# tviic2d6mddr register map
Vendor: Cypress Semiconductor; Series: tviic2d6mddr; File version: 1.0
CPU: CM7 r0p1, little endian, MPU, FPU, VTOR, 3 interrupt priority bits
Registers are 32-bit, read-write, reset 0x0 unless marked. A register's access mark holds for its fields unless they carry their own. Offsets are from the block's base; [hi:lo] are bit positions; lines under a group give offsets from that group; {n}, {i} and the like mark numbered series; 'fields as' and 'values as' point back to an identical list.

## VIDEOSS0 (part 10 of 18) — Video and Graphics Subsystem IP
Base 0x40A00000
0x80000 VIDEOIO group — Video I/O Core
  0x00 SUBIO group — Sub Interface
    0x10000 COMPENG group — Composition Engine
      {0x7400+0x400*l} LAYERBLEND{l} group (l=1..5) — LayerBlend #{l} (Display, Alpha Plane {l})
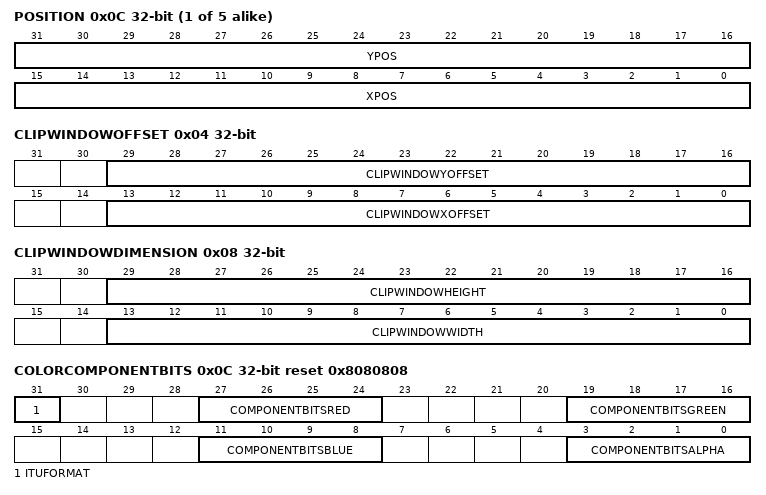
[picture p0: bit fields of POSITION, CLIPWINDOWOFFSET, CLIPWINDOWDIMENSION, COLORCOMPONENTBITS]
        0x0C POSITION — Position of secondary (overlay) input frame
          [31:16] YPOS — vertical position, first pixel is at 0, format s15 (twos complement) (format is signed integer)
          [15:0] XPOS — horizontal position, first pixel is at 0, format s15 (twos complement) (format is signed integer)
      0x8C00 EXTSRC8 group — ExtSrc #8 (Display)
        0x00 STATICCONTROL — ExtSrc static control register
          [8] STARTSEL — Start select selects the mode to start processing operations.
            0=INPUT (Free running mode, use the incoming command word as trigger to start processing.); 1=LOCAL (Keep to local start configuration, use external kick or SW trigger to start processing. The behavior is similar to fetch units.)
          [0] SHDEN — Enables shadowing of all RWS type registers (0=write_through, 1=shadowed).
        0x04 CLIPWINDOWOFFSET — Clip window offset, to generate a clipping of the frame. It has to be within the input frame.
          [29:16] CLIPWINDOWYOFFSET — Clip window offset in Y direction, relative to the frame origin.
          [13:0] CLIPWINDOWXOFFSET — Clip window offset in X direction, relative to the frame origin.
        0x08 CLIPWINDOWDIMENSION — Define the clip window dimension. If the clip window feature is enabled this dimension is used for the new frame dimension. Note that the clip window has to be smaller or equal to the original frame dimensions. The new frame has to be within the active area of the original frame.
          [29:16] CLIPWINDOWHEIGHT — Clip window height in pixels minus one.
          [13:0] CLIPWINDOWWIDTH — Clip window width in pixels minus one.
        0x0C COLORCOMPONENTBITS reset 0x8080808 — Color component size of raw input data. Please note that the width must be equal or lower than the output width.
          [31] ITUFORMAT — When ComponentBitsRed/Green/Blue is set to 10 and this mode enabled (value 1), then input format is considered 8.2 instead of 10.0 bits (max color is 1020 instead of 1023). This is compliant to ITU 656 standard.
          [27:24] COMPONENTBITSRED — Component size of red channel [0-10].
          [19:16] COMPONENTBITSGREEN — Component size of green channel [0-10].
          [11:8] COMPONENTBITSBLUE — Component size of blue channel [0-10].
          [3:0] COMPONENTBITSALPHA — Component size of alpha channel [0-8].
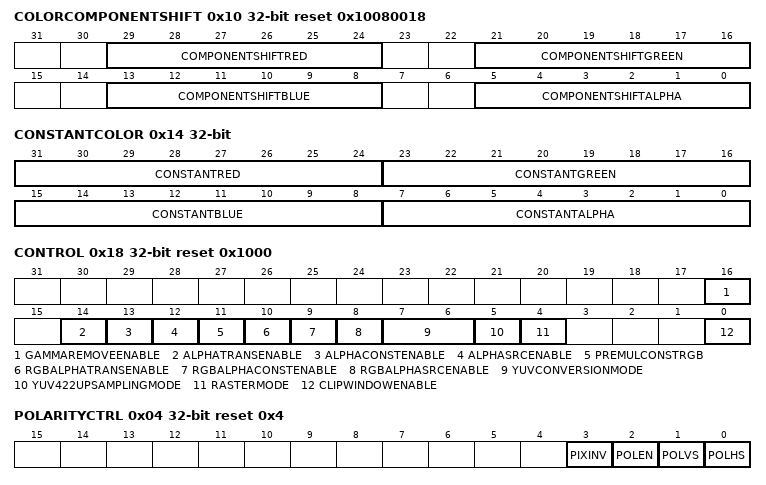
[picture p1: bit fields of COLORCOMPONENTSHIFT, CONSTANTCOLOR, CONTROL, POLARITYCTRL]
        0x10 COLORCOMPONENTSHIFT reset 0x10080018 — Color component offset of raw input data.
          [29:24] COMPONENTSHIFTRED — Offset for red component.
          [21:16] COMPONENTSHIFTGREEN — Offset for green component.
          [13:8] COMPONENTSHIFTBLUE — Offset for blue component.
          [5:0] COMPONENTSHIFTALPHA — Offset for alpha component.
        0x14 CONSTANTCOLOR
          [31:24] CONSTANTRED — Red or Y (luma).
          [23:16] CONSTANTGREEN — Green or U (chroma).
          [15:8] CONSTANTBLUE — Blue or V (chroma).
          [7:0] CONSTANTALPHA — Alpha.
        0x18 CONTROL reset 0x1000 — Common control settings.
          [16] GAMMAREMOVEENABLE — Value 1 enables the stage to remove a gamma from RGB components.
          [14] ALPHATRANSENABLE — Value 1 enables transparent alpha for computing the output alpha. When disabled transparent alpha is set to 1.
          [13] ALPHACONSTENABLE — Value 1 enables constant alpha for computing the output alpha. When disabled constant alpha is set to 1.
          [12] ALPHASRCENABLE — Value 1 enables source alpha for computing the output alpha. When disabled source alpha is set to 1.
          [11] PREMULCONSTRGB — When enabled (value 1) the values given by ConstantRed/Green/Blue are used instead of alpha for source RGB pre-multiply. Settings RGBAlphaSrc/Const/TransEnable have no effect then.
          [10] RGBALPHATRANSENABLE — Value 1 enables transparent alpha (0 or 1 depending on RGB matching ConstantColor setting) for RGB pre-multiply. When disabled transparent alpha is set to 1.
          [9] RGBALPHACONSTENABLE — Value 1 enables constant alpha (ConstAlpha field) for RGB pre-multiply. When disabled constant alpha is set to 1.
          [8] RGBALPHASRCENABLE — Value 1 enables source alpha (extracted from input stream) for RGB pre-multiply. When disabled source alpha is set to 1.
          [7:6] YUVCONVERSIONMODE — Enables different kind of YUV to RGB conversions.
            0=OFF (No conversion. Input data must be RGB.); 1=ITU601 (Conversion from YCbCr (YUV) to RGB according to ITU recommendation BT.601-6 (standard definition TV). Input range is 16..235 for Y and 16..240 for U/V.); 2=ITU601_FR (Conversion from YCbCr (YUV) to RGB according to ITU recommendation BT.601-6, but assuming full range YUV inputs (0..255). Most typically used for computer graphics (e.g. for JPEG encoding).); 3=ITU709 (Conversion from YCbCr (YUV) to RGB according to ITU recommendation BT.709-5 part 2 (high definition TV). Input range is 16..235 for Y and 16..240 for U/V.)
          [5] YUV422UPSAMPLINGMODE — Selects a method for horizontal up-sampling when RasterMode is YUV422.
            0=REPLICATE (Replicate mode for interspersed samples (UV samples between Y samples).); 1=INTERPOLATE (Interpolate mode for coaligned samples (UV samples at Y sample positions).)
          [4] RASTERMODE — Selects a method how generate output samples from input stream.
            0=NORMAL (Input stream is RGB(A) or YUV 4:4:4.); 1=YUV422 (Input stream is packed YUV 4:2:2.)
          [0] CLIPWINDOWENABLE — Value 1 enables the clip window feature.
        0x1C CONTROLTRIGGER wo reset not defined — ExtSrc unit trigger token generation
          [0] SHDTOKGEN — Write a 1 to this field for the extsrc unit to perform a shadow load with the next start of operation and set the rld bit in the start of frame control word (generate shadow load token for subsequent units).
        0x20 START wo reset not defined — ExtSrc unit start register
          [0] START — Writing a one starts processing, use this only for debug purposes.
  0x20000 DISENG0 group — Display Engine
    0x00 DISENGCFG0 group — Top-Level Configuration
      0x00 CTL reset 0x1 — Display engine control register.
        [0] DSPCLKDIVIDE — Controls generation of display clock signals for display stream.
          0=DIV1 (External display clock signal has pixel clock frequency.); 1=DIV2 (External display clock signal has twice the pixel clock frequency.)
      0x04 POLARITYCTRL reset 0x4 — Polarity control for TCon input and corresponding top-level output (TCon by-pass port).
        [3] PIXINV — Inversion of RGB data.
          0=NONINV (No inversion of pixel data); 1=INV (Pixel data inverted (1. complement))
        [2] POLEN — Polarity of Data_Enable signal.
          0=LOW (Low active); 1=HIGH (High active)
        [1] POLVS — Polarity of vsync signal.
          0=LOW (Low active); 1=HIGH (High active)
        [0] POLHS — Polarity of hsync signal.
          0=LOW (Low active); 1=HIGH (High active)
      0x10 SIGSELECT — Tap selection for Signature.
        [1:0] SIG_SELECT — Selects a source for Sig unit.
          0=NONE (No source.); 1=FRAMEGEN (Source is FrameGen output.); 2=GAMMACOR (Source is GammaCor output.); 3=DITHER (Source is Dither output.)
      0x14 HISTOGRAMSELECT — Tap selection for Histogram.
        [1:0] HISTOGRAM_SELECT — Selects a source for Histogram unit.
          values as VIDEOIO.DISENG0.DISENGCFG0.SIGSELECT.SIG_SELECT
      0x20 DUMPSELECT — Tap selection for Frame Dump.
        [9:8] DUMP_SELECT — Selects a source for FrameDump unit.
          values as VIDEOIO.DISENG0.DISENGCFG0.SIGSELECT.SIG_SELECT
    0x1000 SIG0 group — Signature Unit
      0x00 STATICCONTROL reset 0x8000000 — Global configuration shared by all evaluation windows.
        [31:24] ERRTHRESRESET — ErrThresReset must be programmed to value less than 255. Number of consecutive frames without signature violation before StsSigError is reset for an evaluation window. 0 means that each frame without violation will reset the status. The internal counter compared against this threshold is reset with each frame that has violation.
        [23:16] ERRTHRES — Number of frames with signature violation before StsSigError is set for an evaluation window. These frames do not need to be consecutive. 0 means that each frame with violation will set the status. The internal counter compared against this threshold is reset when 'ErrThreshReset' consecutive frames without signature violation occur.
        [4] SHDLDSEL — Source select for events that will load shadow registers into the active configuration.
          0=LOCAL (Shadows are loaded at start of frame for each evaluation window for which ShdLdReq has been set.); 1=GLOBAL (Shadows of all evaluation windows are loaded synchronous to the display stream (shadow load token received on frame input port).)
        [0] SHDEN — Enables shadow registers for RWS type fields (0 = write through, 1 = shadowed).
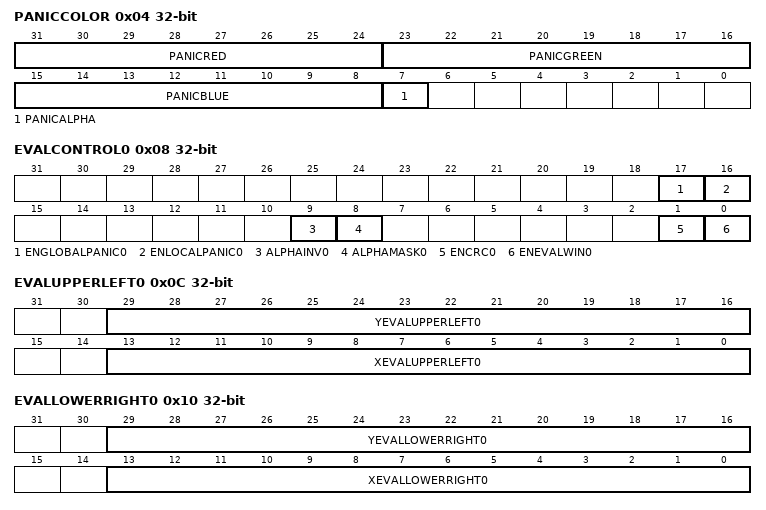
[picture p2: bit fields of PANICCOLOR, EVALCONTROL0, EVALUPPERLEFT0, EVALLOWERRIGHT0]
      0x04 PANICCOLOR — Overlay color for evaluation windows in panic mode.
        [31:24] PANICRED — Red color component.
        [23:16] PANICGREEN — Green color component.
        [15:8] PANICBLUE — Blue color component.
        [7] PANICALPHA — Alpha mask bit.
      0x08 EVALCONTROL0 — Control settings for evaluation window 0.
        [17] ENGLOBALPANIC0 — When enabled (value 1) the error status of this window (StsSigError) will activate the panic mode of the display stream's Frame Generator, which can switch to another display mode in response.
        [16] ENLOCALPANIC0 — When enabled (value 1) the error status this window (StsSigError) will replace all pixels inside the window by a constant color on the display. Skip regions due to other evaluation windows on top are not modified. AlphaMask, when enabled, is not considered for this replacement.
        [9] ALPHAINV0 — When enabled (value 1) the effect of AlphaMask is inverted (pixels with alpha bit = 1 are ignored then).
        [8] ALPHAMASK0 — When enabled (value 1) pixels with alpha bit = 0 are ignored for signature computation.
        [1] ENCRC0 — When enabled (value 1) the measured signature is checked against a reference value (SigCRCRef).
        [0] ENEVALWIN0 — When enabled (value 1) a CRC signature is computed for all pixels inside this evaluation window (SigCRC). When this bit is cleared, the internal status for this window is reset (StsSigError bit and frame counters).
      0x0C EVALUPPERLEFT0 — Upper left corner of evaluation window 0.
        [29:16] YEVALUPPERLEFT0 — Y coordinate.
        [13:0] XEVALUPPERLEFT0 — X coordinate.
      0x10 EVALLOWERRIGHT0 — Lower right corner of evaluation window 0.
        [29:16] YEVALLOWERRIGHT0 — Y coordinate.
        [13:0] XEVALLOWERRIGHT0 — X coordinate.
      0x14 SIGCRCREDREF0 reset 0xFFFFFFFF — Reference signature of red channel for evaluation window 0.
        [31:0] SIGCRCREDREF0 — Reference value that is compared against measured SigCRCRed value.
      0x18 SIGCRCGREENREF0 reset 0xFFFFFFFF — Reference signature of green channel for evaluation window 0.
        [31:0] SIGCRCGREENREF0 — Reference value that is compared against measured SigCRCGreen value.
      0x1C SIGCRCBLUEREF0 reset 0xFFFFFFFF — Reference signature of blue channel for evaluation window 0.
        [31:0] SIGCRCBLUEREF0 — Reference value that is compared against measured SigCRCBlue value.
      0x20 SIGCRCRED0 ro reset 0xFFFFFFFF — Measured signature of red channel for evaluation window 0.
        [31:0] SIGCRCRED0 — CRC values from red channel.
      0x24 SIGCRCGREEN0 ro reset 0xFFFFFFFF — Measured signature of green channel for evaluation window 0.
        [31:0] SIGCRCGREEN0 — CRC values from green channel.
      0x28 SIGCRCBLUE0 ro reset 0xFFFFFFFF — Measured signature of blue channel for evaluation window 0.
        [31:0] SIGCRCBLUE0 — CRC values from blue channel.
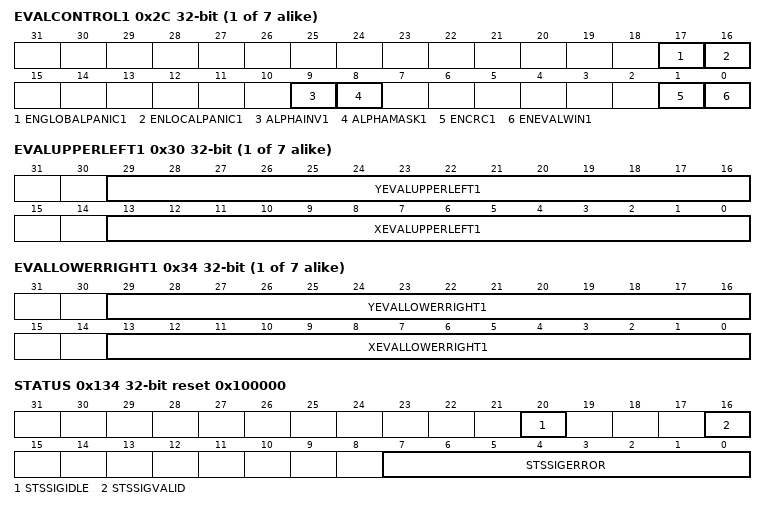
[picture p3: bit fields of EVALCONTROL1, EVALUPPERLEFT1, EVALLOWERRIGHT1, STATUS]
      {0x8+0x24*l} EVALCONTROL{l} (l=1..7) — Control settings for evaluation window {l}.
        [17] ENGLOBALPANIC{l} — See EnGlobalPanic0.
        [16] ENLOCALPANIC{l} — See EnLocalPanic0.
        [9] ALPHAINV{l} — See AlphaInv0.
        [8] ALPHAMASK{l} — See AlphaMask0.
        [1] ENCRC{l} — See EnCRC0.
        [0] ENEVALWIN{l} — See EnEvalWin0.
      {0xC+0x24*l} EVALUPPERLEFT{l} (l=1..7) — Upper left corner of evaluation window {l}.
        [29:16] YEVALUPPERLEFT{l} — See YEvalUpperLeft0.
        [13:0] XEVALUPPERLEFT{l} — See XEvalUpperLeft0.
      {0x10+0x24*l} EVALLOWERRIGHT{l} (l=1..7) — Lower right corner of evaluation window {l}.
        [29:16] YEVALLOWERRIGHT{l} — See YEvalLowerRight0.
        [13:0] XEVALLOWERRIGHT{l} — See XEvalLowerRight0.
      {0x14+0x24*l} SIGCRCREDREF{l} reset 0xFFFFFFFF (l=1..7) — Reference signature of red channel for evaluation window {l}.
        [31:0] SIGCRCREDREF{l} — See SigCRCRedRef0.
      {0x18+0x24*l} SIGCRCGREENREF{l} reset 0xFFFFFFFF (l=1..7) — Reference signature of green channel for evaluation window {l}.
        [31:0] SIGCRCGREENREF{l} — See SigCRCGreenRef0.
      {0x1C+0x24*l} SIGCRCBLUEREF{l} reset 0xFFFFFFFF (l=1..7) — Reference signature of blue channel for evaluation window {l}.
        [31:0] SIGCRCBLUEREF{l} — See SigCRCBlueRef0.
      {0x20+0x24*l} SIGCRCRED{l} ro reset 0xFFFFFFFF (l=1..7) — Measured signature of red channel for evaluation window {l}.
        [31:0] SIGCRCRED{l} — See SigCRCRed0.
      {0x24+0x24*l} SIGCRCGREEN{l} ro reset 0xFFFFFFFF (l=1..7) — Measured signature of green channel for evaluation window {l}.
        [31:0] SIGCRCGREEN{l} — See SigCRCGreen0.
      {0x28+0x24*l} SIGCRCBLUE{l} ro reset 0xFFFFFFFF (l=1..7) — Measured signature of blue channel for evaluation window {l}.
        [31:0] SIGCRCBLUE{l} — See SigCRCBlue0.
      0x128 SHADOWLOAD — Shadow load control register.
        [7:0] SHDLDREQ — Shadow load request for each evaluation window (bit index = window index). Writing a '1' to a bit will load the shadows into the active configuration for that window at start of next frame. Writing a '0' has no effect. The flag is reset by HW once the shadows have been loaded. A shadow load interrupt signal is generated when shadows have been loaded for at least one evaluation window. Has only effect when ShdLdSel is set to LOCAL.
      0x12C CONTINUOUSMODE — Signature operation mode control.
        [0] ENCONT — EnCont = 0: disables continuous mode. Signatures will be generated only once and in idle state after completion of measurement. In this 'ONE_TIME' mode the signature must be triggered by 'Kick' field. EnCont = 1: enables continuous mode. Write '1' to this field, signature starts and measures every incoming frame until EnCont is turned to 0. 'Kick' has no effect when 'EnCont' = 1.
      0x130 SOFTWAREKICK wo reset not defined — Signature measurement trigger.
        [0] KICK — ContinueMode.EnCont=0: Write '1' to this field in order to start signature computation with next frame. ContinueMode.EnCont=1: This field is ignored.
      0x134 STATUS ro reset 0x100000 — Module status.
        [20] STSSIGIDLE — StsSigIdle = 1: Signature is in Idle state. StsSigIdle = 0: Signature runs.
        [16] STSSIGVALID — Measured signature values are valid. This flag is set when the SigCRC fields have been updated for all enabled evaluation windows. In that case also the corresponding interrupt event is triggered. It is reset when SW writes a '1' to the 'Kick' field in order to start a new measurement.
        [7:0] STSSIGERROR — Error status bits for all evaluation windows (bit index = window index). When a bit is set it means that measured signature value is different from reference value (SigCRCRef). The bit is set when EnCRC is active and a certain number of frames have a violation (ErrThres). It is reset when the reference check for evaluation window is disabled (EnEvalWin or EnCRC) or in case a certain number of consecutive frames have no violation (ErrThresReset). The value corresponds to the panic status of this evaluation window.
    0x1400 HISTOGRAM0 group — Histogram Unit
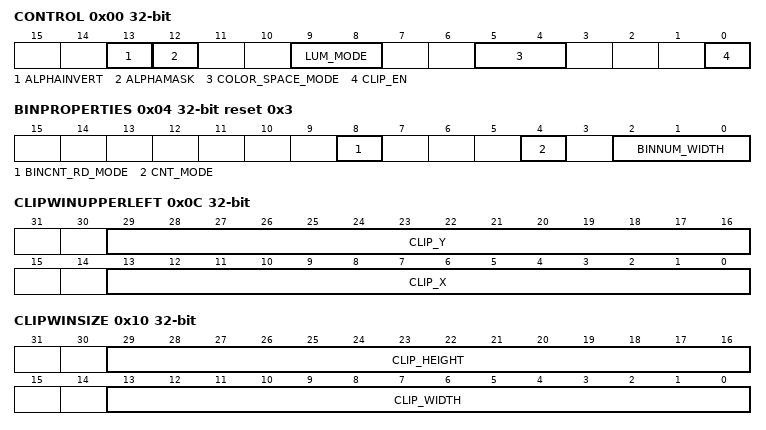
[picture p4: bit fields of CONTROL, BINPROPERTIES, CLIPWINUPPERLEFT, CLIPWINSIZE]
      0x00 CONTROL — Controls some settings concerning input components and alpha mask.
        [13] ALPHAINVERT — Value 1 inverts the effect of the alpha mask mode when enabled (pixels with alpha value smaller or equal 0.5 are affecting the histogram bins).
        [12] ALPHAMASK — Value 1 enables the alpha mask mode. In this mode only pixels with an alpha value larger than 0.5 are affecting the histogram bins.
        [9:8] LUM_MODE — If a histogram for luma or luminance is required, the conversion formula for luma (Y component according to BT.601) or luminance (Y component according to BT.709) can be selected here. Luma or luminance calculation should only be applied if RGB components in range [0..255] are delivered directly at histogram input or when YCrCb components are converted to RGB by the appropriate setting of register field color_space_mode. Luma or luminance counting is delivered in first (component0) histogram. (format is unsigned integer)
          0=NO_CONV (Component0 for first histogram is counted as it is.); 1=LUMA (Component0 for first histogram is replaced by luma, which is calculated from RGB input components according to BT.601.); 2=LUMINANCE (Component0 for first histogram is replaced by luminance, which is calculated from RGB input components according to BT.709.)
        [5:4] COLOR_SPACE_MODE — Assuming that YUV(YCrCb) color components according to BT.601 or BT.709 are provided at histogram input the appropriate conversion to RGB components in [0,255] range can be selected here. (format is unsigned integer)
          0=NO_CONV (No color space conversion of input components is applied.); 1=YUV2RGB_BT601 (YUV input components as described in BT.601 are converted to RGB in [0,255] range.); 2=YUV2RGB_BT709 (YUV input components as described in BT.709 are converted to RGB in [0,255] range.)
        [0] CLIP_EN — Switch for clip window. If enabled all pixels outside the clip window are not taken into account. (format is unsigned integer)
          0=DISABLE (Clip window is switched off.); 1=ENABLE (Clip window is switched on.)
      0x04 BINPROPERTIES reset 0x3 — Configures the histogram bins.
        [8] BINCNT_RD_MODE — The field controls if the actual bin count or the sum of all bin counts up to actual bin count is provided in registers RsltComp0Bincnt, RsltComp1Bincnt and RsltComp2Bincnt. (format is unsigned integer)
          0=BINCNT (Actual bin cnt is provided.); 1=BINCNT_ACCU (Bin count sum is provided.)
        [4] CNT_MODE — Counter mode, which controls the way the bin values are accumulated. (format is unsigned integer)
          0=NEAREST (Counter of nearest bin is incremented.); 1=LINEAR (Counters of the 2 nearest bins are increased by one minus the distance to bin center (normalized between 0 and 1), it works only for first (component0) histogram, reading of component1/2 histogram results in undefined data.)
        [2:0] BINNUM_WIDTH — 2**binnum_width is the number of bins in a histogram. (format is unsigned integer)
          3=BINS_8 (There are 8 bins, addressable with 3bit.); 4=BINS_16 (There are 16 bins, addressable with 4bit.); 5=BINS_32 (There are 32 bins, addressable with 5bit.); 6=BINS_64 (There are 64 bins, addressable with 6bit.)
      0x08 BINCNTTHRESH — Bin counter threshold value.
        [28:0] BINCNT_THRESH — Bin counters below this threshold will be reported as 0. This threshold value will also affect the BINCNT_ACCU mode where 0 will be added for all bin counters below the threshold. (format is unsigned integer)
      0x0C CLIPWINUPPERLEFT — Coordinates of upper left corner of clip window.
        [29:16] CLIP_Y — Y coordinate of upper left corner of clip window. (format is unsigned integer)
        [13:0] CLIP_X — X coordinate of upper left corner of clip window. (format is unsigned integer)
      0x10 CLIPWINSIZE — Dimensions of clip window.
        [29:16] CLIP_HEIGHT — Height of clip window, given minus one. (format is unsigned integer)
        [13:0] CLIP_WIDTH — Width of clip window, given minus one. (format is unsigned integer)
      0x14 RSLTRDY ro — Measurement result status.
        [0] RSLT_RDY — A one indicates that measurement results (in registers Rslt...) are valid and can be read. (format is unsigned integer)
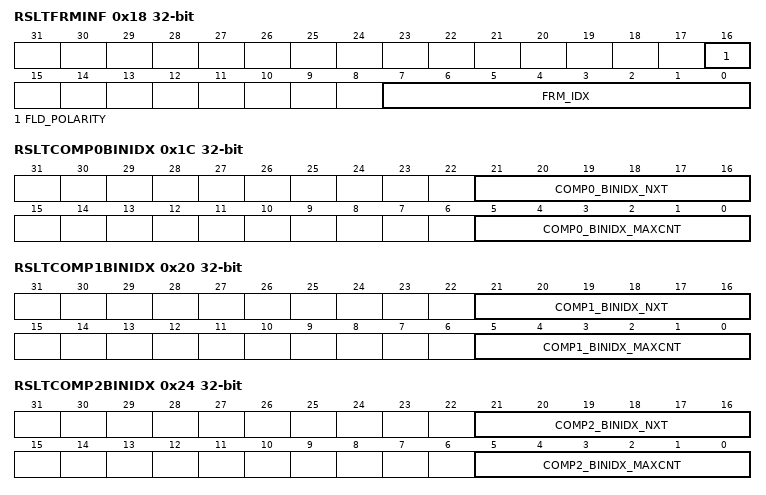
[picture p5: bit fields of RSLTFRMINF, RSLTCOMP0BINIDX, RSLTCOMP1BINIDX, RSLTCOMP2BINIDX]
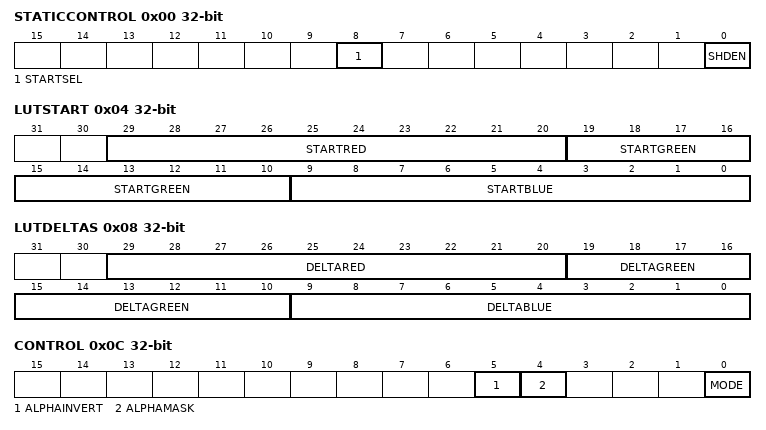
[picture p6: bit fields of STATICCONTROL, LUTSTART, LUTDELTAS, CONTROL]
      0x18 RSLTFRMINF ro — Additional information on the measurement results.
        [16] FLD_POLARITY — Returns field polarity of the measured frame. This read value of this field is undefined in display stream context; use in storage, content or safety stream context only. (format is unsigned integer)
        [7:0] FRM_IDX — Each frame passing the histogram unit gets an index, which is the value of a wrapped around counter, which counts the frames independent from how the histogram unit is configured. The index of the frame of the ongoing readout can be read here. In display stream context, if the display operation ends (framegen is switched off and sequence complete occurs) this frame index is reset to 0. (format is unsigned integer)
      0x1C RSLTCOMP0BINIDX ro — Results of frame measurement for component 0.
        [21:16] COMP0_BINIDX_NXT — Do not use this filed. The index of the bin, that will be next accessed by register RsltComp0Bincnt. In the case of RGB pixels, component0 means the red value, in the case of YUV pixels, component 0 means the Y value. If luma/luminance calculation is switched on by field lum_mode component0 is the calculated luma/luminance. (format is unsigned integer)
        [5:0] COMP0_BINIDX_MAXCNT — The index of the bin of the component 0 histogram, which contains the highest counter value, which were read until now for the ongoing readout. In the case of RGB pixels, component 0 means the red value, in the case of YUV pixels, component0 means the Y value. If luma/luminance calculation is switched on by field lum_mode component0 is the calculated luma/luminance. (format is unsigned integer)
      0x20 RSLTCOMP1BINIDX ro — Results of frame measurement for component 1.
        [21:16] COMP1_BINIDX_NXT — The index of the bin, that will be next accessed by register RsltComp1Bincnt. In the case of RGB pixels, component 1 means the green value. In the case of YUV pixels, component 1 means the Cb value. (format is unsigned integer)
        [5:0] COMP1_BINIDX_MAXCNT — The index of the bin of the component 1 histogram, which contains the highest counter value, which were read until now for the ongoing readout. In the case of RGB pixels, component 1 means the green value. In the case of YUV pixels, component 1 means the Cb value. (format is unsigned integer)
      0x24 RSLTCOMP2BINIDX ro — Results of frame measurement for component 2.
        [21:16] COMP2_BINIDX_NXT — The index of the bin, that will be next accessed by register RsltComp2Bincnt. In the case of RGB pixels, component 2 means the blue value. In the case of YUV pixels, component 2 means the Cr value. (format is unsigned integer)
        [5:0] COMP2_BINIDX_MAXCNT — The index of the bin of the component 2 histogram, which contains the highest counter value, which were read until now for the ongoing readout. In the case of RGB pixels, component 2 means the blue value. In the case of YUV pixels, component 2 means the Cr value. (format is unsigned integer)
      0x28 RSLTCOMP0SUM ro — Sum of all component 0 values.
        [31:0] COMP0_SUM — Sum of all component 0 values. In the case of RGB pixels, component 0 means the red value, in the case of YUV pixels, component 0 means the Y value. If luma/luminance calculation is switched on by field lum_mode, component 0 is the calculated luma/luminance. If the read value is 0xFFFFFFFF a counter overflow has occurred and the read value should not be used (this can only happen for frame dimensions beyond 2^12 * 2^12). (format is unsigned integer)
      0x2C RSLTCOMP1SUM ro — Sum of all component 1 values.
        [31:0] COMP1_SUM — Sum of all component 1 values. In the case of RGB pixels, component 1 means the green value. In the case of YUV pixels, component 1 means the Cb value. If the read value is 0xFFFFFFFF a counter overflow has occurred and the read value should not be used (this can only happen for frame dimensions beyond 2^12 * 2^12). (format is unsigned integer)
      0x30 RSLTCOMP2SUM ro — Sum of all component 2 values.
        [31:0] COMP2_SUM — Sum of all component 2 values. In the case of RGB pixels, component 2 means the blue value. In the case of YUV pixels, component 2 means the Cr value. If the read value is 0xFFFFFFFF a counter overflow has occurred and the read value should not be used (this can only happen for frame dimensions beyond 2^12 * 2^12). (format is unsigned integer)
      0x34 RSLTCOMP0BINCNT ro — Bin counters of component 0 histogram. This register do NOT support debugger access followed by software access (they clear on read)
        [28:0] COMP0_BINCNT — Counter of current bin number in component 0 histogram. In the case of RGB pixels, component 0 means the red value, in the case of YUV pixels, component 0 means the Y value. (format is unsigned integer)
      0x38 RSLTCOMP1BINCNT ro — Bin counters of component 1 histogram. This register do NOT support debugger access followed by software access (they clear on read)
        [28:0] COMP1_BINCNT — Counter of current bin number in component 1 histogram. In the case of RGB pixels, component 1 means the green value. In the case of YUV pixels, component 1 means the Cb value. (format is unsigned integer)
      0x3C RSLTCOMP2BINCNT ro — Bin counters of component 2 histogram. This register do NOT support debugger access followed by software access (they clear on read)
        [28:0] COMP2_BINCNT — Counter of current bin index in component 2 histogram. In the case of RGB pixels, component 2 means the blue value. In the case of YUV pixels, component 2 means the Cb value. (format is unsigned integer)
      0x40 FRMSTRTTRIG wo reset not defined — Triggers for loading shadow registers and starting measurement with next input frame.
        [0] MSRMNT_STRT_TRIG — Writing value 1 into this field initiates the measurement of the next frame. (format is unsigned integer)
    0x1800 GAMMACOR20 group — Gamma Correction Unit 2
      0x00 STATICCONTROL reset 0xE — Static control settings.
        [3] REDWRITEENABLE — Write enable for the red color sampling point entries.
        [2] GREENWRITEENABLE — Write enable for the green color sampling point entries.
        [1] BLUEWRITEENABLE — Write enable for the blue color sampling point entries.
        [0] SHDEN — Enables shadowing of all RWS type registers (0=write_through, 1=shadowed).
      0x04 LUTSTART wo — Start values for look-up table programming.
        [29:20] STARTRED — Start value for red or luma (Y) channel. (format is unsigned integer)
        [19:10] STARTGREEN — Start value for green or chroma (U) channel. (format is unsigned integer)
        [9:0] STARTBLUE — Start value for blue or chroma (V) channel. (format is unsigned integer)
      0x08 LUTDELTAS wo reset not defined — Delta values for look-up table programming.
        [29:20] DELTARED — Delta value for red or luma (Y) channel. (format is signed integer)
        [19:10] DELTAGREEN — Delta value for green or chroma (U) channel. (format is signed integer)
        [9:0] DELTABLUE — Delta value for blue or chroma (V) channel. (format is signed integer)
      0x0C CONTROL — Dynamic control settings.
        [5] ALPHAINVERT — Value 1 inverts the effect of the alpha mask mode when enabled (pixels with alpha value greater or equal 0.5 are by-passed).
        [4] ALPHAMASK — Value 1 enables the alpha mask mode. In this mode all pixels with an alpha value smaller than 0.5 are by-passed unchanged.
        [0] MODE — Operation mode for gamma correction unit
          0=NEUTRAL (Module in neutral mode, input data is bypassed to the output.); 1=GAMMACOR (Module in gamma correction mode.)
    0x1C00 MATRIX0 group — Color Matrix
      0x00 STATICCONTROL — Color Matrix static control register
        [0] SHDEN — Enables shadowing of all RWS type registers (0=write_through, 1=shadowed).
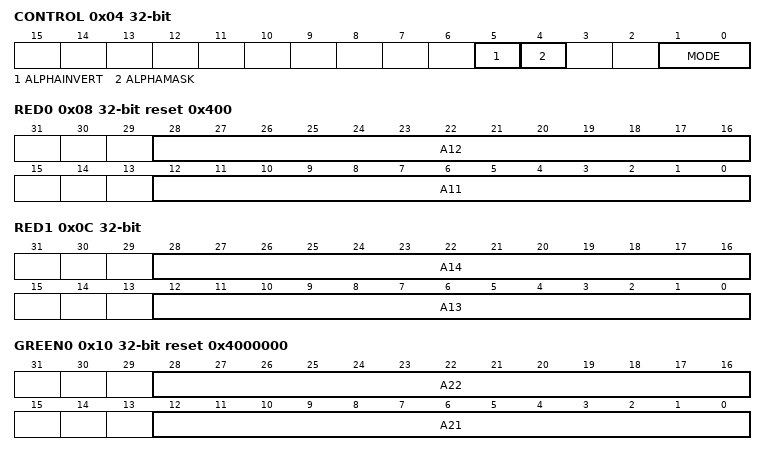
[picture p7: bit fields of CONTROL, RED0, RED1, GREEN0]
      0x04 CONTROL — Color Matrix control register
        [5] ALPHAINVERT — Value 1 inverts the effect of the alpha mask mode when enabled (pixels with alpha value greater or equal 0.5 are by-passed).
        [4] ALPHAMASK — Value 1 enables the alpha mask mode. In this mode all pixels with an alpha value smaller than 0.5 are by-passed unchanged.
        [1:0] MODE — Operation mode for color matrix
          0=NEUTRAL (Module in neutral mode, input data is bypassed); 1=MATRIX (Module in matrix mode, input data is multiplied with matrix values); 2=PREMUL (Module in alpha pre-multiplication mode, input color is multiplied with input alpha); 3=RSVD (N/A)
      0x08 RED0 reset 0x400 — Matrix values for calculation of the red output value.
        [28:16] A12 — Value for green input. (format is signed fix-point 3.10)
        [12:0] A11 — Value for red input. (format is signed fix-point 3.10)
      0x0C RED1 — Matrix values for calculation of the red output value.
        [28:16] A14 — Value for alpha input. (format is signed fix-point 3.10)
        [12:0] A13 — Value for blue input. (format is signed fix-point 3.10)
      0x10 GREEN0 reset 0x4000000 — Matrix values for calculation of the green output value.
        [28:16] A22 — Value for green input. (format is signed fix-point 3.10)
        [12:0] A21 — Value for red input. (format is signed fix-point 3.10)
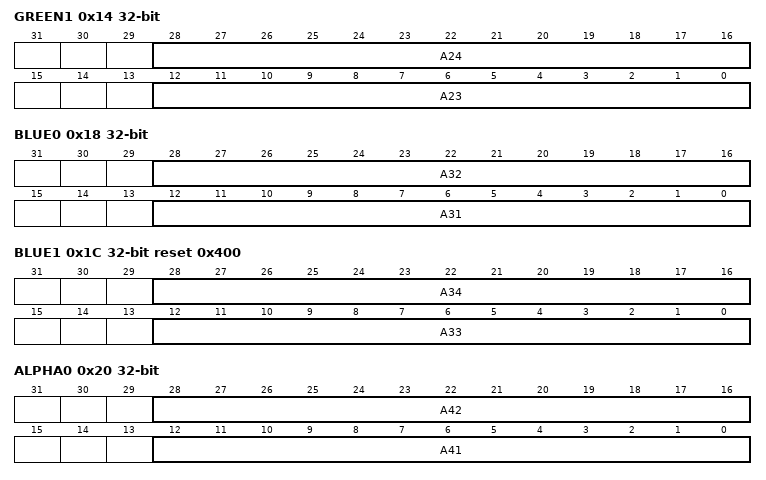
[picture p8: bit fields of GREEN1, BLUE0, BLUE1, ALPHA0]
      0x14 GREEN1 — Matrix values for calculation of the green output value.
        [28:16] A24 — Value for alpha input. (format is signed fix-point 3.10)
        [12:0] A23 — Value for blue input. (format is signed fix-point 3.10)
      0x18 BLUE0 — Matrix values for calculation of the blue output value.
        [28:16] A32 — Value for green input. (format is signed fix-point 3.10)
        [12:0] A31 — Value for red input. (format is signed fix-point 3.10)
      0x1C BLUE1 reset 0x400 — Matrix values for calculation of the blue output value.
        [28:16] A34 — Value for alpha input. (format is signed fix-point 3.10)
        [12:0] A33 — Value for blue input. (format is signed fix-point 3.10)
      0x20 ALPHA0 — Matrix values for calculation of the alpha output value.
        [28:16] A42 — Value for green input. (format is signed fix-point 3.10)
        [12:0] A41 — Value for red input. (format is signed fix-point 3.10)
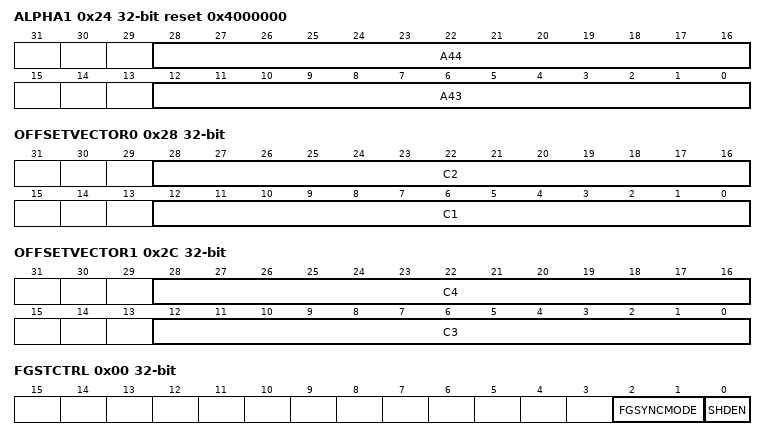
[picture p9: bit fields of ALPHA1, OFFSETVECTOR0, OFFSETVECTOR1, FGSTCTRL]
      0x24 ALPHA1 reset 0x4000000 — Matrix values for calculation of the alpha output value.
        [28:16] A44 — Value for alpha input. (format is signed fix-point 3.10)
        [12:0] A43 — Value for blue input. (format is signed fix-point 3.10)
      0x28 OFFSETVECTOR0 — Offset vectors for red and green output.
        [28:16] C2 — Green output offset. (format is signed integer)
        [12:0] C1 — Red output offset. (format is signed integer)
      0x2C OFFSETVECTOR1 — Offset vectors for blue and alpha output.
        [28:16] C4 — Alpha output offset. Note that the 8-bit alpha input is up-scaled to 10-bit, before the matrix and this offset is applied, and down-scaled to 8-bit for output afterwards. (format is signed integer)
        [12:0] C3 — Blue output offset. (format is signed integer)
    0x2000 FRAMEGEN0 group — Frame Generator
      0x00 FGSTCTRL — FrameGen Static Control Register
        [2:1] FGSYNCMODE — Determines the operating mode of the framegen unit for side-by-side synchronization. The framegen unit programmed as master generates synchronization pulses. The framegen units programmed as slaves are synchronized to the master unit. There must be only one framegen unit programmed acting as master.
          0=OFF (No side-by-side synchronization.); 1=MASTER (Framegen is master.); 2=SLAVE_CYC (Framegen is slave. Runs in cyclic synchronization mode.); 3=SLAVE_ONCE (Framegen is slave. Runs in one time synchronization mode.)
        [0] SHDEN — Enables shadowing for RWS type configuration fields. Otherwise shadow registers are immediately updated when written.
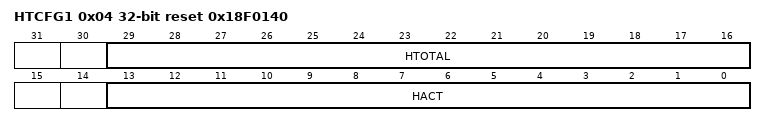
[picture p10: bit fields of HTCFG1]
      0x04 HTCFG1 reset 0x18F0140 — FrameGen Horizontal Timing Config Register 1
        [29:16] HTOTAL — Total horizontal size of frame in pixels. (Set value +1 is the total horizontal size of frame) Htotal shall be greater or equal than Hact + Hsbp. Note1: Valid setup for horizontal video timing contains parameters Hact, Htotal, Hsbp and, if enabled, Hsync. Note2: If SRAdj==1 then Htotal[0] shall be equal the value of SREven (for sec. channel only).
        [13:0] HACT — Horizontal size of active display area in pixels. Hact shall be greater or equal than 4. Note: Valid setup for horizontal video timing contains parameters Hact, Htotal, Hsbp and, if enabled, Hsync.
